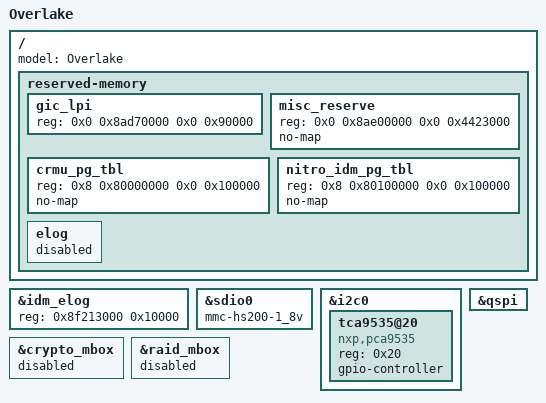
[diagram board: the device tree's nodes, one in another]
// SPDX-License-Identifier: (GPL-2.0 or BSD-3-Clause)
/*
 *  Copyright(c) 2018 Broadcom
 */

/dts-v1/;

#define NUM_CRYPTO	0
#define NUM_RAID	0
#define ENABLE_NAND	0
#define ENABLE_SSP0	0
#define ENABLE_SSP1	0
#define ENABLE_SDCARD	0
#define ENABLE_PWM	0
#define ENABLE_ENET	0
#define ENABLE_MDIO	0
#define ENABLE_USB1	0
#define ENABLE_UART2	0
#define ENABLE_UART3	0

#define ENABLE_I2C0	1
#define ENABLE_I2C1	1
#define ENABLE_EMMC	1
#define ENABLE_OPTEE	1

#ifndef NUM_PAXB
#define NUM_PAXB	1
#define ENABLE_PCIE0	1
#endif

#ifndef ENABLE_PAXC
#define ENABLE_PAXC	1
#endif

#define ENABLE_PAXB_IOMMU	1
#define ENABLE_PAXC_IOMMU	1
#define ENABLE_FS4_IOMMU	0

#include "../../stingray-board-base.dtsi"

/ {
	model = "Overlake";

	reserved-memory {
		/* GIC LPI tables */
		gic_lpi {
			reg = <0x0 0x8ad70000 0x0 0x90000>;
		};

		/* Nitro FW, nitro Crash, Bl31, Bl32 and elog */
		misc_reserve {
			reg = <0x0 0x8ae00000 0x0 0x4423000>;
			no-map;
		};

		crmu_pg_tbl {
			reg = <0x8 0x80000000 0x0 0x100000>;
			no-map;
		};

		/* IOMMU page tables for Nitro IDM access to SoC */
		nitro_idm_pg_tbl {
			reg = <0x8 0x80100000 0x0 0x100000>;
			no-map;
		};

		elog {
			status = "disabled";
		};
	};
};

&idm_elog {
	reg = <0x8f213000 0x10000>;
};

&sdio0 {
	mmc-hs200-1_8v;
};

&i2c0 {
	tca9535@20 {
		compatible = "nxp,pca9535";
		reg = <0x20>;
		gpio-controller;
		#gpio-cells = <2>;
	};
};

&qspi {
	status = "okay";
};

&crypto_mbox {
	status = "disabled";
};

&raid_mbox {
	status = "disabled";
};
